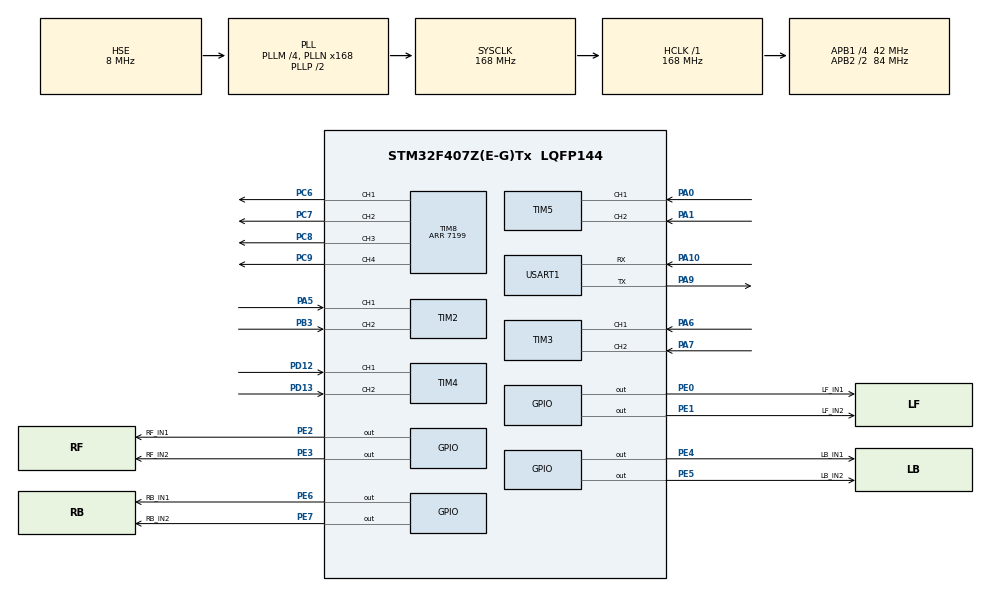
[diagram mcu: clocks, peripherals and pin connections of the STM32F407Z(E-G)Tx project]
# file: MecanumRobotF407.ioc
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Dma.Request0=USART1_RX
Dma.Request1=USART1_TX
Dma.USART1_RX.0.Direction=DMA_PERIPH_TO_MEMORY
Dma.USART1_RX.0.FIFOMode=DMA_FIFOMODE_DISABLE
Dma.USART1_RX.0.Instance=DMA2_Stream2
Dma.USART1_RX.0.MemDataAlignment=DMA_MDATAALIGN_BYTE
Dma.USART1_RX.0.MemInc=DMA_MINC_ENABLE
Dma.USART1_RX.0.Mode=DMA_NORMAL
Dma.USART1_RX.0.PeriphDataAlignment=DMA_PDATAALIGN_BYTE
Dma.USART1_RX.0.PeriphInc=DMA_PINC_DISABLE
Dma.USART1_RX.0.Priority=DMA_PRIORITY_LOW
Dma.USART1_TX.1.Direction=DMA_MEMORY_TO_PERIPH
Dma.USART1_TX.1.FIFOMode=DMA_FIFOMODE_DISABLE
Dma.USART1_TX.1.Instance=DMA2_Stream7
Dma.USART1_TX.1.MemDataAlignment=DMA_MDATAALIGN_BYTE
Dma.USART1_TX.1.MemInc=DMA_MINC_ENABLE
Dma.USART1_TX.1.Mode=DMA_NORMAL
Dma.USART1_TX.1.PeriphDataAlignment=DMA_PDATAALIGN_BYTE
Dma.USART1_TX.1.PeriphInc=DMA_PINC_DISABLE
Dma.USART1_TX.1.Priority=DMA_PRIORITY_LOW
Mcu.Family=STM32F4
Mcu.Name=STM32F407Z(E-G)Tx
Mcu.Package=LQFP144
NVIC.DMA2_Stream2_IRQn=true\:0\:0\:false\:false\:true\:false\:true\:true
NVIC.DMA2_Stream7_IRQn=true\:0\:0\:false\:false\:true\:false\:true\:true
NVIC.PriorityGroup=NVIC_PRIORITYGROUP_4
NVIC.TIM6_DAC_IRQn=true\:1\:0\:true\:false\:true\:true\:true\:true
NVIC.USART1_IRQn=true\:0\:0\:false\:false\:true\:true\:true\:true
PA0-WKUP.GPIO_PuPd=GPIO_PULLUP
PA0-WKUP.Signal=S_TIM5_CH1
PA1.GPIO_PuPd=GPIO_PULLUP
PA1.Signal=S_TIM5_CH2
PA10.Mode=Asynchronous
PA10.Signal=USART1_RX
PA13.Mode=Serial_Wire
PA13.Signal=SYS_JTMS-SWDIO
PA14.Mode=Serial_Wire
PA14.Signal=SYS_JTCK-SWCLK
PA5.GPIO_PuPd=GPIO_PULLUP
PA5.Signal=S_TIM2_CH1_ETR
PA6.GPIO_PuPd=GPIO_PULLUP
PA6.Signal=S_TIM3_CH1
PA7.GPIO_PuPd=GPIO_PULLUP
PA7.Signal=S_TIM3_CH2
PA9.Mode=Asynchronous
PA9.Signal=USART1_TX
PB3.GPIO_PuPd=GPIO_PULLUP
PB3.Signal=S_TIM2_CH2
PC6.Signal=S_TIM8_CH1
PC7.Signal=S_TIM8_CH2
PC8.Signal=S_TIM8_CH3
PC9.Signal=S_TIM8_CH4
PD12.GPIO_PuPd=GPIO_PULLUP
PD12.Signal=S_TIM4_CH1
PD13.GPIO_PuPd=GPIO_PULLUP
PD13.Signal=S_TIM4_CH2
PE0.GPIO_Label=LF_IN1
PE0.Signal=GPIO_Output
PE1.GPIO_Label=LF_IN2
PE1.Signal=GPIO_Output
PE2.GPIO_Label=RF_IN1
PE2.Signal=GPIO_Output
PE3.GPIO_Label=RF_IN2
PE3.Signal=GPIO_Output
PE4.GPIO_Label=LB_IN1
PE4.Signal=GPIO_Output
PE5.GPIO_Label=LB_IN2
PE5.Signal=GPIO_Output
PE6.GPIO_Label=RB_IN1
PE6.Signal=GPIO_Output
PE7.GPIO_Label=RB_IN2
PE7.Signal=GPIO_Output
PH0-OSC_IN.Mode=HSE-External-Oscillator
PH0-OSC_IN.Signal=RCC_OSC_IN
PH1-OSC_OUT.Mode=HSE-External-Oscillator
PH1-OSC_OUT.Signal=RCC_OSC_OUT
ProjectManager.HeapSize=0x200
ProjectManager.StackSize=0x400
ProjectManager.TargetToolchain=MDK-ARM V5.32
RCC.48MHZClocksFreq_Value=84000000
RCC.AHBFreq_Value=168000000
RCC.APB1CLKDivider=RCC_HCLK_DIV4
RCC.APB1Freq_Value=42000000
RCC.APB1TimFreq_Value=84000000
RCC.APB2CLKDivider=RCC_HCLK_DIV2
RCC.APB2Freq_Value=84000000
RCC.APB2TimFreq_Value=168000000
RCC.CortexFreq_Value=168000000
RCC.HCLKFreq_Value=168000000
RCC.HSE_VALUE=8000000
RCC.HSI_VALUE=16000000
RCC.LSE_VALUE=32768
RCC.PLLM=4
RCC.PLLN=168
RCC.PLLSourceVirtual=RCC_PLLSOURCE_HSE
RCC.SYSCLKFreq_VALUE=168000000
RCC.SYSCLKSource=RCC_SYSCLKSOURCE_PLLCLK
RCC.VCOOutputFreq_Value=336000000
SH.S_TIM2_CH1_ETR.0=TIM2_CH1,Encoder_Interface
SH.S_TIM2_CH2.0=TIM2_CH2,Encoder_Interface
SH.S_TIM3_CH1.0=TIM3_CH1,Encoder_Interface
SH.S_TIM3_CH2.0=TIM3_CH2,Encoder_Interface
SH.S_TIM4_CH1.0=TIM4_CH1,Encoder_Interface
SH.S_TIM4_CH2.0=TIM4_CH2,Encoder_Interface
SH.S_TIM5_CH1.0=TIM5_CH1,Encoder_Interface
SH.S_TIM5_CH2.0=TIM5_CH2,Encoder_Interface
SH.S_TIM8_CH1.0=TIM8_CH1,PWM Generation1 CH1
SH.S_TIM8_CH2.0=TIM8_CH2,PWM Generation2 CH2
SH.S_TIM8_CH3.0=TIM8_CH3,PWM Generation3 CH3
SH.S_TIM8_CH4.0=TIM8_CH4,PWM Generation4 CH4
TIM2.EncoderMode=TIM_ENCODERMODE_TI12
TIM2.IC1Filter=4
TIM3.EncoderMode=TIM_ENCODERMODE_TI12
TIM3.IC2Filter=4
TIM6.Period=19999
TIM6.Prescaler=83
TIM8.Channel-PWM\ Generation1\ CH1=TIM_CHANNEL_1
TIM8.Channel-PWM\ Generation2\ CH2=TIM_CHANNEL_2
TIM8.Channel-PWM\ Generation3\ CH3=TIM_CHANNEL_3
TIM8.Channel-PWM\ Generation4\ CH4=TIM_CHANNEL_4
TIM8.Period=7199
USART1.VirtualMode=VM_ASYNC
VP_TIM6_VS_ClockSourceINT.Mode=Enable_Timer
VP_TIM8_VS_ClockSourceINT.Mode=Internal
board=custom

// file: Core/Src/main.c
/* USER CODE BEGIN Header */
/**
  ******************************************************************************
  * @file           : main.c
  * @brief          : Main program body
  ******************************************************************************
  * @attention
  *
  * Copyright (c) 2026 STMicroelectronics.
  * All rights reserved.
  *
  * This software is licensed under terms that can be found in the LICENSE file
  * in the root directory of this software component.
  * If no LICENSE file comes with this software, it is provided AS-IS.
  *
  ******************************************************************************
  */
/* USER CODE END Header */
#include "main.h"
#include "dma.h"
#include "tim.h"
#include "usart.h"
#include "gpio.h"

/* USER CODE BEGIN Includes */
#include <robot_ctrl.h>
#include <protocol.h>
/* USER CODE END Includes */

/* USER CODE BEGIN PV */
uint8_t rx_buffer; //串口接收缓存区
/* USER CODE END PV */

void SystemClock_Config(void);

int main(void)
{

  /* USER CODE BEGIN 1 */
	Robot_Init();
	HAL_TIM_Base_Start_IT(&htim6);
	HAL_UART_Receive_IT(&huart1, &rx_buffer, 1);
  /* USER CODE END 1 */

  /* MCU Configuration--------------------------------------------------------*/

  /* Reset of all peripherals, Initializes the Flash interface and the Systick. */
  HAL_Init();

  /* Configure the system clock */
  SystemClock_Config();

  /* Initialize all configured peripherals */
  MX_GPIO_Init();
  MX_DMA_Init();
  MX_TIM2_Init();
  MX_TIM3_Init();
  MX_TIM4_Init();
  MX_TIM5_Init();
  MX_TIM6_Init();
  MX_TIM8_Init();
  MX_USART1_UART_Init();

  /* Infinite loop */
  while (1)
  {

  }
}

void SystemClock_Config(void)
{
  RCC_OscInitTypeDef RCC_OscInitStruct = {0};
  RCC_ClkInitTypeDef RCC_ClkInitStruct = {0};

  /** Configure the main internal regulator output voltage
  */
  __HAL_RCC_PWR_CLK_ENABLE();
  __HAL_PWR_VOLTAGESCALING_CONFIG(PWR_REGULATOR_VOLTAGE_SCALE1);

  /** Initializes the RCC Oscillators according to the specified parameters
  * in the RCC_OscInitTypeDef structure.
  */
  RCC_OscInitStruct.OscillatorType = RCC_OSCILLATORTYPE_HSE;
  RCC_OscInitStruct.HSEState = RCC_HSE_ON;
  RCC_OscInitStruct.PLL.PLLState = RCC_PLL_ON;
  RCC_OscInitStruct.PLL.PLLSource = RCC_PLLSOURCE_HSE;
  RCC_OscInitStruct.PLL.PLLM = 4;
  RCC_OscInitStruct.PLL.PLLN = 168;
  RCC_OscInitStruct.PLL.PLLP = RCC_PLLP_DIV2;
  RCC_OscInitStruct.PLL.PLLQ = 4;
  if (HAL_RCC_OscConfig(&RCC_OscInitStruct) != HAL_OK)
  {
    Error_Handler();
  }

  /** Initializes the CPU, AHB and APB buses clocks
  */
  RCC_ClkInitStruct.ClockType = RCC_CLOCKTYPE_HCLK|RCC_CLOCKTYPE_SYSCLK
                              |RCC_CLOCKTYPE_PCLK1|RCC_CLOCKTYPE_PCLK2;
  RCC_ClkInitStruct.SYSCLKSource = RCC_SYSCLKSOURCE_PLLCLK;
  RCC_ClkInitStruct.AHBCLKDivider = RCC_SYSCLK_DIV1;
  RCC_ClkInitStruct.APB1CLKDivider = RCC_HCLK_DIV4;
  RCC_ClkInitStruct.APB2CLKDivider = RCC_HCLK_DIV2;

  if (HAL_RCC_ClockConfig(&RCC_ClkInitStruct, FLASH_LATENCY_5) != HAL_OK)
  {
    Error_Handler();
  }
}

/* USER CODE BEGIN 4 */

void HAL_TIM_PeriodElapsedCallback(TIM_HandleTypeDef *htim)
{

		// 检查是不是 TIM6 (防止别的定时器干扰)
    if (htim->Instance == TIM6)
    {
        // 闭环控制
        // 流程：读取编码器 -> 对比目标 -> 算 PID -> 调整 PWM
        Robot_ControlLoop();

        // 向上汇报 (给 ROS 发数据)
        // 流程：把现在的速度、位置打包 -> 用 DMA 发给上位机
        Protocol_SendFeedback();
    }

}
void HAL_UART_RxCpltCallback(UART_HandleTypeDef *huart)
{
    // 检查是不是 USART1
    if (huart->Instance == USART1)
    {
        // A. 把这 1 个字节扔进协议状态机处理
        // (如果是包头就存起来，如果是数据就拼包，拼满了就自动执行 SetTarget)
        Protocol_ProcessByte(rx_buffer);

        // 重新开启中断
        HAL_UART_Receive_IT(&huart1, &rx_buffer, 1);
    }
}

/* USER CODE END 4 */

void Error_Handler(void)
{
  __disable_irq();
  while (1)
  {
  }
}
